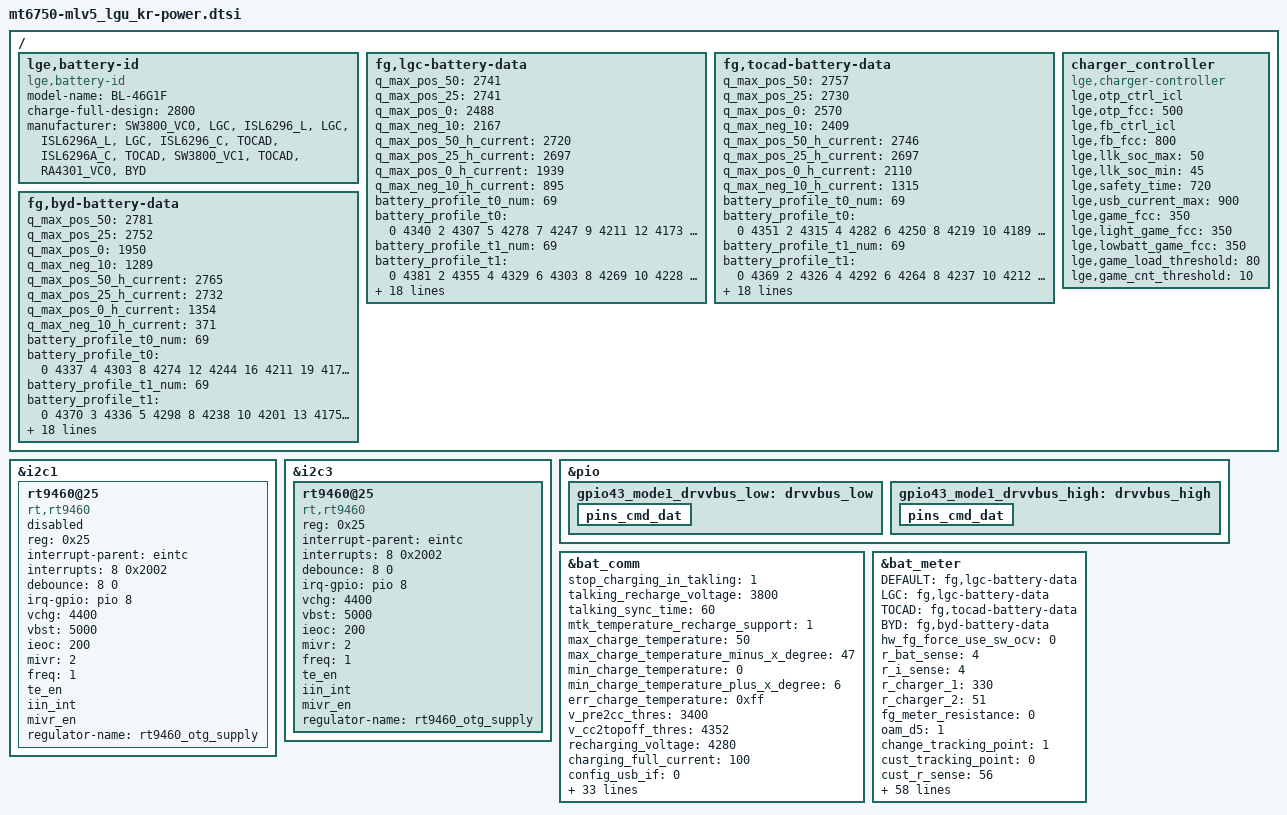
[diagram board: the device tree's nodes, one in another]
/*
 * LG Electronics LV5 power device tree source
 *
 * Copyright (c) 2016 LG Electronics Co., Ltd.
 *              http://www.lge.com
 *
 */

&i2c1 {
	rt9460@25 {
		status = "disabled";
		compatible = "rt,rt9460";
		reg = <0x25>;
		interrupt-parent = <&eintc>;
		interrupts = <8 0x2002>;
		debounce = <8 0>;
		irq-gpio = <&pio 8 0x2002>;
		vchg = <4400>;
		vbst = <5000>;
		ieoc = <200>;
		mivr = <2>;
		freq = <1>;
		te_en;
		iin_int;
		mivr_en;

		regulator-name = "rt9460_otg_supply";
	};
};

&i2c3 {
	rt9460@25 {
		status = "okay";
		compatible = "rt,rt9460";
		reg = <0x25>;
		interrupt-parent = <&eintc>;
		interrupts = <8 0x2002>;
		debounce = <8 0>;
		irq-gpio = <&pio 8 0x2002>;
		vchg = <4400>;
		vbst = <5000>;
		ieoc = <200>;
		mivr = <2>;
		freq = <1>;
		te_en;
		iin_int;
		mivr_en;

		regulator-name = "rt9460_otg_supply";
	};
};

/ {
	lge,battery-id{
		compatible = "lge,battery-id";

		model-name = "BL-46G1F";
		charge-full-design = <2800>;

		/* Auth ID - Vendor */
		manufacturer =
			"SW3800_VC0", "LGC",
			"ISL6296_L", "LGC",
			"ISL6296A_L", "LGC",
			"ISL6296_C", "TOCAD",
			"ISL6296A_C", "TOCAD",
			"SW3800_VC1", "TOCAD",
			"RA4301_VC0", "BYD";
	};
};

&pio {
	gpio43_mode1_drvvbus_low: drvvbus_low{
		pins_cmd_dat {
			/delete-property/ pins;
			/delete-property/ slew-rate;
			/delete-property/ output-low;
		};
	};
	gpio43_mode1_drvvbus_high: drvvbus_high{
		pins_cmd_dat {
			/delete-property/ pins;
			/delete-property/ slew-rate;
			/delete-property/ output-high;
		};
	};
};

&bat_comm {
	/* cust_charging.h */
	/* stop charging while in talking mode */
	stop_charging_in_takling = <1 >;
	talking_recharge_voltage = <3800 >;
	talking_sync_time = <60 >;

	/* Battery Temperature Protection */
	mtk_temperature_recharge_support = <1 >;
	max_charge_temperature = <50 >;
	max_charge_temperature_minus_x_degree = <47 >;
	min_charge_temperature = <0 >;
	min_charge_temperature_plus_x_degree = <6 >;
	err_charge_temperature = <0xff >;

	/* Linear Charging Threshold */
	v_pre2cc_thres = <3400 >;	/* unit: mV */
	v_cc2topoff_thres = <4352 >;
	recharging_voltage = <4280 >;
	charging_full_current = <100 >;	/* unit: mA */

	/* Charging Current Setting */
	config_usb_if = <0 >;
	usb_charger_current_suspend = <0 >;	/* Unit: 0.01 mA */
	usb_charger_current_unconfigured = <7000 >;	/* Unit: 0.01 mA */
	usb_charger_current_configured = <50000 >;	/* Unit: 0.01 mA */
	usb_charger_current = <50000 >;	/* Unit: 0.01 mA */
	ac_charger_current = <320000 >;	/* Unit: 0.01 mA */
	ac_charger_input_current = <90000 >;	/* Unit: 0.01 mA */
	non_std_ac_charger_current = <50000 >;	/* Unit: 0.01 mA */
	charging_host_charger_current = <90000 >;	/* Unit: 0.01 mA */
	apple_0_5a_charger_current = <50000 >;	/* Unit: 0.01 mA */
	apple_1_0a_charger_current = <90000 >;	/* Unit: 0.01 mA */
	apple_2_1a_charger_current = <90000 >;	/* Unit: 0.01 mA */

	/* charger error check */
	bat_low_temp_protect_enable = <0 >;
	v_charger_enable = <0 >;	/* 1:on , 0:off */
	v_charger_max = <10500 >;	/* unit: mV */
	v_charger_min = <4400 >;

	/*  Tracking TIME */
	onehundred_percent_tracking_time = <10 >;	/* Unit: second */
	npercent_tracking_time = <20 >;	/* Unit: second */
	sync_to_real_tracking_time = <60 >;	/* Unit: second */
	v_0percent_tracking = <3450 >;	/* Unit: mV */

	/* High battery support */
	high_battery_voltage_support = <1 >;

	mtk_pump_express_plus_support = <0 >;
	ta_start_battery_soc = <1 >;
	ta_stop_battery_soc = <100 >;
	ta_ac_charging_current = <220000 >;

	ta_ac_12v_input_current = <180000 >;
	ta_ac_9v_input_current = <180000 >;
	ta_ac_7v_input_current = <180000 >;

	ta_9v_support = <1 >;
	ta_12v_support = <0 >;

	typec_high_input_current = <150000>;
	typec_high_charging_current = <150000>;
	typec_medium_input_current = <150000>;
	typec_medium_charging_current = <150000>;
};


/* battery_profile */
&bat_meter {
	/* battery id */
	DEFAULT = "fg,lgc-battery-data";
	LGC = "fg,lgc-battery-data";
	TOCAD = "fg,tocad-battery-data";
	BYD = "fg,byd-battery-data";

	/* cust_battery_meter.h */
	hw_fg_force_use_sw_ocv = <0 >;
	/* ADC resistor  */
	r_bat_sense = <4 >;
	r_i_sense = <4 >;
	r_charger_1 = <330 >;
	r_charger_2 = <51 >;
	fg_meter_resistance = <0 >;

	/* Discharge percentage, 1: D5, 0: D2 */
	oam_d5 = <1 >;

	change_tracking_point = <1 >;
	/* SW OCV tracking setting */
	cust_tracking_point = <0 >;
	cust_r_sense = <56 >;
	cust_hw_cc = <0 >;
	aging_tuning_value = <103 >;
	cust_r_fg_offset = <0 >;
	ocv_board_compesate = <0 >;
	r_fg_board_base = <1000 >;
	r_fg_board_slope = <1000 >;
	car_tune_value = <99 >;

	/* HW Fuel gague  */
	current_detect_r_fg = <10 >;	/* Unit: mA */
	minerroroffset = <1000 >;
	fg_vbat_average_size = <18 >;
	r_fg_value = <10 >;	/* Unit: mOhm */

	/* HW Fuel gague 2.0*/
	difference_hwocv_rtc = <20 >;
	difference_hwocv_swocv = <30 >;
	difference_swocv_rtc = <30 >;

	difference_hwocv_vbat = <30>;
	difference_vbat_rtc = <30>;
	difference_swocv_rtc_pos = <15>;

	max_swocv = <1>;

	difference_voltage_update = <20>;
	aging1_load_soc = <70>;
	aging1_update_soc = <30>;
	batterypseudo100 = <95>;

	batterypseudo1 = <3>;

	q_max_by_sys = <1>;			/*8. qmax variant by system drop voltage.*/
	q_max_sys_voltage = <3350>;
	shutdown_gauge0 = <0>;
	shutdown_gauge1_xmins = <0>;
	shutdown_gauge1_mins = <60>;

	shutdown_system_voltage = <3300>;
	charge_tracking_time = <60>;
	discharge_tracking_time = <10>;

	recharge_tolerance = <2>;

	/* SW Fuel Gauge */
	max_hwocv = <5 >;
	max_vbat = <90 >;

	/* HW Fuel gague 1.0*/
	cust_poweron_delta_capacity_tolrance = <40 >;
	cust_poweron_low_capacity_tolrance = <5 >;
	cust_poweron_max_vbat_tolrance = <90 >;
	cust_poweron_delta_vbat_tolrance = <30 >;
	cust_poweron_delta_hw_sw_ocv_capacity_tolrance = <10 >;

	/* Fixed battery temperature */
	fixed_tbat_25 = <0 >;
	/* Dynamic change wake up period of battery thread when suspend */
	vbat_normal_wakeup = <3600 >;	/* Unit: mV */
	vbat_low_power_wakeup = <3500 >;	/* Unit: mV */
	normal_wakeup_period = <5400 >;	/* Unit: second */
	low_power_wakeup_period = <300 >;	/* Unit: second */
	close_poweroff_wakeup_period = <30 >;	/* Unit: second */

	init_soc_by_sw_soc = <1 >;
	sync_ui_soc_imm =<0>;
	mtk_enable_aging_algorithm = <1>;
	md_sleep_current_check = <1>;
	q_max_by_current = <0>;

	/* SOC track to SWOCV */
	cust_tracking_gap = <15 >;	/* start tracking gap */
	cust_trackingoffset = <0 >;	/* force offset to shift soc to 0 */
	cust_trackingen = <0 >;	/* 0:disable, 1:enable */

	/* keep min uisoc until voltage less than customization voltage of min uisoc */
	cust_min_uisoc_percentage = <2 >;
	cust_min_uisoc_voltage = <3300 >;

	rbat_pull_up_r = <62000 >;
	rbat_pull_up_volt = <1800 >;
};

/{
	/* LGC 2800mA Battery 3.4V cut off */
	fg,lgc-battery-data {
		/* Qmax for 0mA */
		q_max_pos_50 = <2741 >;
		q_max_pos_25 = <2741 >;
		q_max_pos_0 = <2488 >;
		q_max_neg_10 = <2167 >;
		/* Qmax for 400mA, said high current */
		q_max_pos_50_h_current = <2720 >;
		q_max_pos_25_h_current = <2697 >;
		q_max_pos_0_h_current = <1939 >;
		q_max_neg_10_h_current = <895 >;

		battery_profile_t0_num = <69 >;
		battery_profile_t0 = <
			0 4340 	2 4307 	5 4278 	7 4247 	9 4211
			12 4173 	14 4143 	16 4118 	18 4097 	21 4076
			23 4051 	25 4024 	28 3997 	30 3974 	32 3953
			35 3935 	37 3919 	39 3903 	42 3887 	44 3873
			46 3862 	48 3850 	51 3839 	53 3829 	55 3820
			58 3811 	60 3803 	62 3795 	65 3789 	67 3782
			69 3776 	72 3768 	74 3760 	76 3752 	78 3743
			81 3733 	83 3723 	85 3713 	88 3701 	90 3688
			92 3671 	95 3643 	97 3589 	99 3473 	100 3353
			100 3272 	100 3219 	100 3175 	100 3136 	100 3101
			100 3078 	100 3061 	100 3045 	100 3027 	100 3007
			100 2997 	100 3001 	100 2999 	100 2995 	100 2992
			100 2989 	100 2515 	100 2517 	100 2520 	100 2515
			100 2521 	100 2519 	100 2520 	100 2520
			>;
		battery_profile_t1_num = <69 >;
		battery_profile_t1 = <
			0 4381 	2 4355 	4 4329 	6 4303 	8 4269
			10 4228 	12 4190 	14 4163 	16 4140 	18 4119
			20 4099 	22 4082 	24 4061 	26 4039 	28 4017
			30 3997 	32 3980 	34 3963 	36 3946 	38 3928
			40 3909 	42 3891 	44 3874 	46 3860 	48 3848
			50 3838 	52 3829 	54 3820 	56 3812 	58 3804
			60 3798 	62 3791 	64 3788 	66 3783 	68 3778
			70 3774 	72 3769 	74 3763 	76 3757 	78 3748
			80 3739 	82 3729 	84 3718 	86 3706 	88 3696
			90 3686 	92 3676 	94 3660 	96 3617 	98 3522
			100 3430 	100 3388 	100 3359 	100 3337 	100 3319
			100 3304 	100 3292 	100 3281 	100 3270 	100 3261
			100 3252 	100 3244 	100 3237 	100 3230 	100 3223
			100 3217 	100 3210 	100 3204 	100 3204
			>;
		battery_profile_t2_num = <69 >;
		battery_profile_t2 = <
			0 4389 	2 4356 	4 4329 	5 4304 	7 4280
			9 4258 	11 4236 	13 4214 	15 4193 	16 4171
			18 4151 	20 4131 	22 4111 	24 4092 	25 4074
			27 4057 	29 4038 	31 4018 	33 4001 	35 3986
			36 3972 	38 3959 	40 3944 	42 3929 	44 3914
			45 3894 	47 3875 	49 3859 	51 3847 	53 3836
			55 3828 	56 3819 	58 3813 	60 3805 	62 3799
			64 3794 	65 3788 	67 3783 	69 3779 	71 3775
			73 3771 	74 3766 	76 3761 	78 3752 	80 3744
			82 3737 	84 3727 	85 3714 	87 3700 	89 3685
			91 3680 	93 3676 	94 3669 	96 3639 	98 3552
			100 3411 	100 3104 	100 3035 	100 2997 	100 2971
			100 2956 	100 2947 	100 2941 	100 2934 	100 2929
			100 2927 	100 2926 	100 2921 	100 2921
			>;
		battery_profile_t3_num = <69 >;
		battery_profile_t3 = <
			0 4394 	2 4358 	4 4329 	5 4304 	7 4279
			9 4256 	11 4233 	13 4212 	15 4189 	16 4169
			18 4148 	20 4127 	22 4107 	24 4088 	25 4069
			27 4051 	29 4033 	31 4016 	33 3999 	35 3984
			36 3968 	38 3954 	40 3940 	42 3927 	44 3913
			45 3896 	47 3874 	49 3856 	51 3844 	53 3834
			55 3825 	56 3817 	58 3809 	60 3802 	62 3796
			64 3789 	65 3784 	67 3779 	69 3775 	71 3770
			73 3763 	74 3750 	76 3743 	78 3736 	80 3729
			82 3722 	84 3713 	85 3700 	87 3687 	89 3671
			91 3666 	93 3662 	94 3654 	96 3624 	98 3542
			100 3411 	100 3141 	100 2970 	100 2926 	100 2903
			100 2890 	100 2880 	100 2875 	100 2869 	100 2865
			100 2863 	100 2862 	100 2857 	100 2857
			>;
		r_profile_t0_num = <69 >;
		r_profile_t0 = <
			795 4340 	795 4307 	830 4278 	853 4247 	908 4211
			1018 4173 	1108 4143 	1145 4118 	1163 4097 	1210 4076
			1228 4051 	1223 4024 	1213 3997 	1208 3974 	1208 3953
			1205 3935 	1213 3919 	1215 3903 	1223 3887 	1228 3873
			1245 3862 	1250 3850 	1263 3839 	1268 3829 	1278 3820
			1283 3811 	1308 3803 	1320 3795 	1325 3789 	1360 3782
			1380 3776 	1415 3768 	1438 3760 	1458 3752 	1488 3743
			1528 3733 	1575 3723 	1613 3713 	1673 3701 	1740 3688
			1788 3671 	1835 3643 	1880 3589 	1493 3473 	1383 3353
			1183 3272 	1053 3219 	940 3175 	845 3136 	765 3101
			703 3078 	655 3061 	615 3045 	590 3027 	543 3007
			520 2997 	563 3001 	558 2999 	1350 2995 	978 2992
			1365 2989 	180 2515 	185 2517 	193 2520 	180 2515
			195 2521 	190 2519 	193 2520 	193 2520
			>;
		r_profile_t1_num = <69 >;
		r_profile_t1 = <
			345 4381 	345 4355 	353 4329 	363 4303 	378 4269
			423 4228 	513 4190 	568 4163 	585 4140 	590 4119
			595 4099 	620 4082 	643 4061 	648 4039 	645 4017
			643 3997 	648 3980 	653 3963 	653 3946 	658 3928
			653 3909 	653 3891 	650 3874 	648 3860 	655 3848
			663 3838 	673 3829 	678 3820 	688 3812 	695 3804
			705 3798 	715 3791 	730 3788 	743 3783 	768 3778
			785 3774 	805 3769 	828 3763 	855 3757 	880 3748
			913 3739 	948 3729 	988 3718 	1028 3706 	1078 3696
			1140 3686 	1218 3676 	1308 3660 	1398 3617 	1498 3522
			1578 3430 	1470 3388 	1400 3359 	1350 3337 	1303 3319
			1265 3304 	1233 3292 	1218 3281 	1183 3270 	1155 3261
			1138 3252 	1123 3244 	1095 3237 	1098 3230 	1070 3223
			1068 3217 	1055 3210 	1040 3204 	1020 3204
			>;
		r_profile_t2_num = <69 >;
		r_profile_t2 = <
			145 4389 	145 4356 	143 4329 	143 4304 	140 4280
			143 4258 	145 4236 	143 4214 	148 4193 	145 4171
			145 4151 	150 4131 	153 4111 	155 4092 	160 4074
			163 4057 	168 4038 	168 4018 	173 4001 	175 3986
			178 3972 	185 3959 	185 3944 	188 3929 	185 3914
			170 3894 	160 3875 	148 3859 	145 3847 	145 3836
			148 3828 	145 3819 	150 3813 	150 3805 	155 3799
			158 3794 	158 3788 	160 3783 	163 3779 	163 3775
			165 3771 	163 3766 	165 3761 	160 3752 	165 3744
			173 3737 	178 3727 	183 3714 	188 3700 	188 3685
			203 3680 	223 3676 	255 3669 	278 3639 	313 3552
			403 3411 	765 3104 	603 3035 	508 2997 	435 2971
			398 2956 	380 2947 	358 2941 	358 2934 	330 2929
			320 2927 	318 2926 	318 2921 	323 2921
			>;
		r_profile_t3_num = <69 >;
		r_profile_t3 = <
			98 4394 	98 4358 	98 4329 	98 4304 	95 4279
			95 4256 	95 4233 	98 4212 	95 4189 	100 4169
			100 4148 	100 4127 	100 4107 	103 4088 	105 4069
			108 4051 	108 4033 	110 4016 	110 3999 	115 3984
			115 3968 	120 3954 	123 3940 	128 3927 	130 3913
			128 3896 	113 3874 	103 3856 	100 3844 	100 3834
			100 3825 	103 3817 	103 3809 	105 3802 	108 3796
			110 3789 	113 3784 	115 3779 	118 3775 	120 3770
			115 3763 	103 3750 	105 3743 	105 3736 	108 3729
			110 3722 	110 3713 	110 3700 	110 3687 	108 3671
			113 3666 	120 3662 	128 3654 	125 3624 	140 3542
			163 3411 	280 3141 	425 2970 	315 2926 	270 2903
			235 2890 	213 2880 	198 2875 	183 2869 	170 2865
			165 2863 	160 2862 	160 2857 	145 2857
			>;
	};
	/* TOCAD 2800mA Battery 3.4V cut off */
	fg,tocad-battery-data {
		/* Qmax for 0mA */
		q_max_pos_50 = <2757 >;
		q_max_pos_25 = <2730 >;
		q_max_pos_0 = <2570 >;
		q_max_neg_10 = <2409 >;
		/* Qmax for 400mA, said high current */
		q_max_pos_50_h_current = <2746 >;
		q_max_pos_25_h_current = <2697 >;
		q_max_pos_0_h_current = <2110 >;
		q_max_neg_10_h_current = <1315 >;

		battery_profile_t0_num = <69 >;
		battery_profile_t0 = <
			0 4351 	2 4315 	4 4282 	6 4250 	8 4219
			10 4189 	12 4162 	14 4138 	17 4113 	19 4090
			21 4068 	23 4047 	25 4026 	27 4004 	29 3985
			31 3967 	33 3948 	35 3930 	37 3910 	39 3891
			41 3874 	44 3858 	46 3845 	48 3833 	50 3822
			52 3813 	54 3807 	56 3801 	58 3797 	60 3792
			62 3789 	64 3785 	66 3782 	68 3778 	70 3773
			72 3769 	75 3762 	77 3755 	79 3746 	81 3734
			83 3723 	85 3711 	87 3700 	89 3691 	91 3682
			93 3673 	95 3659 	96 3649 	97 3645 	97 3640
			98 3636 	98 3633 	98 3629 	98 3625 	99 3621
			99 3616 	99 3612 	99 3608 	99 3603 	99 3599
			99 3594 	99 3590 	100 3585 	100 3581 	100 3577
			100 3573 	100 3569 	100 3564 	100 3400
			>;
		battery_profile_t1_num = <69 >;
		battery_profile_t1 = <
			0 4369 	2 4326 	4 4292 	6 4264 	8 4237
			10 4212 	12 4187 	14 4164 	16 4140 	17 4118
			19 4097 	21 4078 	23 4058 	25 4039 	27 4019
			29 4001 	31 3985 	33 3968 	35 3952 	37 3934
			39 3915 	41 3897 	43 3879 	45 3864 	47 3849
			49 3839 	50 3830 	52 3820 	54 3812 	56 3805
			58 3798 	60 3793 	62 3788 	64 3785 	66 3783
			68 3779 	70 3776 	72 3773 	74 3769 	76 3763
			78 3755 	80 3745 	81 3734 	83 3721 	85 3704
			87 3692 	89 3683 	91 3675 	93 3667 	95 3653
			97 3610 	98 3587 	98 3568 	98 3551 	99 3537
			99 3524 	99 3513 	99 3503 	99 3492 	99 3483
			99 3475 	100 3466 	100 3459 	100 3451 	100 3443
			100 3436 	100 3429 	100 3423 	100 3400
			>;
		battery_profile_t2_num = <69 >;
		battery_profile_t2 = <
			0 4386 	2 4357 	4 4335 	5 4314 	7 4292
			9 4271 	11 4250 	13 4228 	15 4207 	16 4186
			18 4165 	20 4144 	22 4124 	24 4104 	26 4085
			27 4067 	29 4048 	31 4030 	33 4014 	35 3997
			37 3982 	38 3968 	40 3953 	42 3936 	44 3917
			46 3896 	48 3878 	49 3864 	51 3852 	53 3842
			55 3833 	57 3825 	58 3817 	60 3811 	62 3804
			64 3798 	66 3793 	68 3788 	69 3783 	71 3779
			73 3775 	75 3770 	77 3765 	79 3758 	80 3750
			82 3742 	84 3729 	86 3716 	88 3697 	90 3688
			91 3686 	93 3683 	95 3678 	97 3642 	99 3538
			100 3348 	100 3141 	100 3064 	100 3030 	100 3010
			100 2997 	100 2989 	100 2979 	100 2972 	100 2965
			100 2960 	100 2957 	100 2952 	100 2952
			>;
		battery_profile_t3_num = <69 >;
		battery_profile_t3 = <
			0 4395 	2 4369 	4 4347 	5 4327 	7 4306
			9 4284 	11 4263 	13 4242 	14 4221 	16 4198
			18 4177 	20 4157 	22 4136 	24 4116 	25 4097
			27 4077 	29 4059 	31 4041 	33 4024 	34 4008
			36 3992 	38 3976 	40 3962 	42 3948 	43 3934
			45 3916 	47 3893 	49 3875 	51 3862 	52 3851
			54 3840 	56 3832 	58 3823 	60 3816 	62 3808
			63 3802 	65 3797 	67 3791 	69 3786 	71 3782
			72 3775 	74 3765 	76 3757 	78 3749 	80 3742
			81 3733 	83 3726 	85 3712 	87 3698 	89 3680
			90 3677 	92 3675 	94 3673 	96 3663 	98 3595
			99 3470 	100 3214 	100 3085 	100 3045 	100 3021
			100 3002 	100 2985 	100 2974 	100 2963 	100 2954
			100 2946 	100 2939 	100 2931 	100 2931
			>;
		r_profile_t0_num = <69 >;
		r_profile_t0 = <
			693 4351 	693 4315 	723 4282 	743 4250 	763 4219
			785 4189 	808 4162 	835 4138 	855 4113 	875 4090
			898 4068 	918 4047 	935 4026 	948 4004 	968 3985
			985 3967 	1000 3948 	1013 3930 	1015 3910 	1013 3891
			1008 3874 	1000 3858 	998 3845 	995 3833 	998 3822
			998 3813 	1010 3807 	1018 3801 	1030 3797 	1045 3792
			1068 3789 	1093 3785 	1123 3782 	1153 3778 	1183 3773
			1218 3769 	1245 3762 	1278 3755 	1315 3746 	1353 3734
			1400 3723 	1453 3711 	1518 3700 	1598 3691 	1700 3682
			1835 3673 	2035 3659 	2125 3649 	2115 3645 	2103 3640
			2093 3636 	2083 3633 	2078 3629 	2063 3625 	2060 3621
			2053 3616 	2035 3612 	2043 3608 	2023 3603 	2003 3599
			2005 3594 	2003 3590 	1970 3585 	1963 3581 	1958 3577
			1953 3573 	1948 3569 	1938 3564 	1520 3400
			>;
		r_profile_t1_num = <69 >;
		r_profile_t1 = <
			423 4369 	423 4326 	448 4292 	470 4264 	488 4237
			505 4212 	520 4187 	543 4164 	558 4140 	568 4118
			573 4097 	580 4078 	585 4058 	588 4039 	588 4019
			590 4001 	593 3985 	590 3968 	588 3952 	580 3934
			570 3915 	563 3897 	553 3879 	548 3864 	540 3849
			545 3839 	553 3830 	555 3820 	560 3812 	565 3805
			568 3798 	575 3793 	580 3788 	590 3785 	608 3783
			623 3779 	640 3776 	660 3773 	683 3769 	705 3763
			728 3755 	753 3745 	788 3734 	825 3721 	865 3704
			928 3692 	1015 3683 	1140 3675 	1333 3667 	1605 3653
			1988 3610 	1973 3587 	1928 3568 	1888 3551 	1863 3537
			1818 3524 	1795 3513 	1760 3503 	1740 3492 	1715 3483
			1710 3475 	1685 3466 	1685 3459 	1633 3451 	1658 3443
			1608 3436 	1625 3429 	1570 3423 	1528 3400
			>;
		r_profile_t2_num = <69 >;
		r_profile_t2 = <
			183 4386 	183 4357 	185 4335 	183 4314 	183 4292
			185 4271 	188 4250 	185 4228 	188 4207 	188 4186
			188 4165 	188 4144 	190 4124 	193 4104 	193 4085
			198 4067 	200 4048 	205 4030 	210 4014 	213 3997
			220 3982 	228 3968 	230 3953 	225 3936 	213 3917
			195 3896 	180 3878 	175 3864 	173 3852 	170 3842
			173 3833 	173 3825 	173 3817 	175 3811 	175 3804
			178 3798 	180 3793 	180 3788 	180 3783 	180 3779
			183 3775 	180 3770 	178 3765 	178 3758 	175 3750
			178 3742 	178 3729 	183 3716 	180 3697 	183 3688
			195 3686 	213 3683 	243 3678 	270 3642 	313 3538
			463 3348 	860 3141 	680 3064 	575 3030 	533 3010
			503 2997 	473 2989 	470 2979 	450 2972 	440 2965
			443 2960 	400 2957 	425 2952 	400 2952
			>;
		r_profile_t3_num = <69 >;
		r_profile_t3 = <
			100 4395 	100 4369 	98 4347 	100 4327 	103 4306
			100 4284 	103 4263 	103 4242 	105 4221 	103 4198
			103 4177 	108 4157 	105 4136 	108 4116 	110 4097
			110 4077 	113 4059 	115 4041 	115 4024 	120 4008
			123 3992 	125 3976 	135 3962 	140 3948 	148 3934
			143 3916 	123 3893 	110 3875 	105 3862 	103 3851
			100 3840 	103 3832 	105 3823 	108 3816 	105 3808
			108 3802 	110 3797 	113 3791 	115 3786 	120 3782
			115 3775 	108 3765 	103 3757 	103 3749 	103 3742
			100 3733 	103 3726 	100 3712 	103 3698 	98 3680
			100 3677 	103 3675 	113 3673 	115 3663 	118 3595
			135 3470 	233 3214 	715 3085 	628 3045 	555 3021
			520 3002 	493 2985 	453 2974 	425 2963 	403 2954
			390 2946 	350 2939 	358 2931 	368 2931
			>;
	};
	/* BYD 2800mA Battery 3.4V cut off */
	fg,byd-battery-data {
		/* Qmax for 0mA */
		q_max_pos_50 = <2781 >;
		q_max_pos_25 = <2752 >;
		q_max_pos_0 = <1950 >;
		q_max_neg_10 = <1289 >;
		/* Qmax for 400mA, said high current */
		q_max_pos_50_h_current = <2765 >;
		q_max_pos_25_h_current = <2732 >;
		q_max_pos_0_h_current = <1354 >;
		q_max_neg_10_h_current = <371 >;

		battery_profile_t0_num = <69 >;
		battery_profile_t0 = <
			0 4337 	4 4303 	8 4274 	12 4244 	16 4211
			19 4170 	23 4109 	27 4064 	31 4035 	35 4007
			39 3979 	43 3956 	46 3936 	50 3919 	54 3901
			58 3883 	62 3862 	66 3839 	70 3815 	74 3794
			77 3777 	81 3762 	85 3743 	89 3710 	93 3647
			97 3531 	98 3475 	99 3449 	99 3431 	100 3418
			100 3408 	100 3401 	100 3395 	100 3389 	100 3385
			100 3381 	100 3378 	100 3374 	100 3369 	100 3366
			100 3362 	100 3359 	100 3355 	100 3352 	100 3349
			100 3346 	100 3341 	100 3338 	100 3335 	100 3332
			100 3330 	100 3326 	100 3323 	100 3319 	100 3317
			100 3314 	100 3311 	100 3309 	100 3306 	100 3303
			100 3301 	100 3299 	100 3296 	100 3293 	100 3289
			100 3286 	100 3283 	100 3280 	100 3280
			>;
		battery_profile_t1_num = <69 >;
		battery_profile_t1 = <
			0 4370 	3 4336 	5 4298 	8 4238 	10 4201
			13 4175 	15 4151 	18 4126 	20 4100 	23 4074
			26 4051 	28 4027 	31 4001 	33 3974 	36 3953
			38 3937 	41 3925 	43 3914 	46 3903 	49 3890
			51 3878 	54 3866 	56 3855 	59 3843 	61 3833
			64 3821 	67 3810 	69 3797 	72 3784 	74 3771
			77 3757 	79 3743 	82 3729 	84 3717 	87 3710
			90 3704 	92 3694 	95 3663 	97 3578 	100 3414
			100 3314 	100 3274 	100 3253 	100 3236 	100 3223
			100 3210 	100 3197 	100 3186 	100 3180 	100 3173
			100 3168 	100 3163 	100 3156 	100 3151 	100 3145
			100 3140 	100 3134 	100 3128 	100 3121 	100 3118
			100 3111 	100 3108 	100 3102 	100 3098 	100 3094
			100 3083 	100 3074 	100 3063 	100 3063
			>;
		battery_profile_t2_num = <69 >;
		battery_profile_t2 = <
			0 4387 	2 4361 	4 4341 	5 4319 	7 4297
			9 4277 	11 4255 	13 4233 	14 4213 	16 4190
			18 4170 	20 4150 	22 4130 	24 4110 	25 4091
			27 4073 	29 4056 	31 4037 	33 4017 	34 4000
			36 3984 	38 3969 	40 3954 	42 3936 	44 3913
			45 3893 	47 3878 	49 3866 	51 3855 	53 3845
			54 3836 	56 3829 	58 3821 	60 3813 	62 3807
			64 3801 	65 3796 	67 3790 	69 3784 	71 3779
			73 3772 	74 3765 	76 3760 	78 3753 	80 3747
			82 3739 	83 3730 	85 3717 	87 3706 	89 3691
			91 3688 	93 3685 	94 3681 	96 3660 	98 3579
			100 3439 	100 3166 	100 3121 	100 3103 	100 3091
			100 3082 	100 3075 	100 3068 	100 3060 	100 3050
			100 3035 	100 3028 	100 3022 	100 3022
			>;
		battery_profile_t3_num = <69 >;
		battery_profile_t3 = <
			0 4396 	2 4371 	4 4349 	5 4330 	7 4308
			9 4288 	11 4266 	13 4245 	14 4224 	16 4202
			18 4181 	20 4160 	22 4140 	23 4120 	25 4101
			27 4081 	29 4063 	30 4045 	32 4028 	34 4010
			36 3994 	38 3978 	39 3964 	41 3949 	43 3932
			45 3909 	47 3888 	48 3874 	50 3862 	52 3851
			54 3842 	56 3833 	57 3825 	59 3817 	61 3810
			63 3803 	65 3797 	66 3792 	68 3786 	70 3780
			72 3773 	74 3760 	75 3751 	77 3744 	79 3735
			81 3728 	83 3723 	84 3712 	86 3702 	88 3689
			90 3679 	92 3677 	93 3675 	95 3669 	97 3625
			99 3528 	100 3352 	100 3097 	100 3019 	100 2981
			100 2952 	100 2935 	100 2925 	100 2916 	100 2903
			100 2896 	100 2897 	100 2886 	100 2886
			>;
		r_profile_t0_num = <69 >;
		r_profile_t0 = <
			1418 4337 	1418 4303 	1390 4274 	1355 4244 	1330 4211
			1323 4170 	1428 4109 	1613 4064 	1655 4035 	1650 4007
			1623 3979 	1603 3956 	1593 3936 	1588 3919 	1583 3901
			1580 3883 	1570 3862 	1565 3839 	1558 3815 	1563 3794
			1565 3777 	1585 3762 	1600 3743 	1625 3710 	1653 3647
			1725 3531 	1690 3475 	1625 3449 	1580 3431 	1550 3418
			1523 3408 	1503 3401 	1490 3395 	1475 3389 	1473 3385
			1455 3381 	1448 3378 	1445 3374 	1443 3369 	1433 3366
			1423 3362 	1405 3359 	1405 3355 	1385 3352 	1398 3349
			1368 3346 	1393 3341 	1370 3338 	1375 3335 	1383 3332
			1328 3330 	1363 3326 	1350 3323 	1368 3319 	1338 3317
			1360 3314 	1293 3311 	1348 3309 	1318 3306 	1303 3303
			1353 3301 	1308 3299 	1308 3296 	1313 3293 	1335 3289
			1368 3286 	1323 3283 	1378 3280 	1340 3280
			>;
		r_profile_t1_num = <69 >;
		r_profile_t1 = <
			825 4370 	825 4336 	848 4298 	868 4238 	1028 4201
			1068 4175 	1070 4151 	1060 4126 	1045 4100 	1030 4074
			1020 4051 	1010 4027 	995 4001 	975 3974 	965 3953
			965 3937 	968 3925 	968 3914 	968 3903 	963 3890
			960 3878 	963 3866 	968 3855 	968 3843 	978 3833
			980 3821 	980 3810 	988 3797 	990 3784 	998 3771
			1003 3757 	1010 3743 	1020 3729 	1035 3717 	1058 3710
			1090 3704 	1133 3694 	1173 3663 	1198 3578 	1290 3414
			1285 3314 	1190 3274 	1145 3253 	1105 3236 	1060 3223
			1030 3210 	1005 3197 	975 3186 	965 3180 	938 3173
			945 3168 	915 3163 	948 3156 	900 3151 	905 3145
			915 3140 	920 3134 	955 3128 	938 3121 	820 3118
			938 3111 	820 3108 	823 3102 	925 3098 	928 3094
			1000 3083 	1000 3074 	1020 3063 	903 3063
			>;
		r_profile_t2_num = <69 >;
		r_profile_t2 = <
			190 4387 	190 4361 	190 4341 	185 4319 	173 4297
			173 4277 	170 4255 	165 4233 	165 4213 	150 4190
			148 4170 	150 4150 	160 4130 	168 4110 	173 4091
			175 4073 	180 4056 	185 4037 	190 4017 	193 4000
			198 3984 	198 3969 	200 3954 	195 3936 	175 3913
			168 3893 	165 3878 	163 3866 	165 3855 	163 3845
			165 3836 	168 3829 	170 3821 	163 3813 	168 3807
			170 3801 	173 3796 	175 3790 	175 3784 	178 3779
			173 3772 	168 3765 	170 3760 	175 3753 	183 3747
			180 3739 	170 3730 	160 3717 	158 3706 	150 3691
			153 3688 	155 3685 	163 3681 	163 3660 	170 3579
			205 3439 	923 3166 	818 3121 	765 3103 	753 3091
			768 3082 	753 3075 	705 3068 	653 3060 	638 3050
			668 3035 	593 3028 	590 3022 	648 3022
			>;
		r_profile_t3_num = <69 >;
		r_profile_t3 = <
			103 4396 	103 4371 	100 4349 	103 4330 	100 4308
			103 4288 	103 4266 	105 4245 	105 4224 	103 4202
			103 4181 	103 4160 	105 4140 	108 4120 	108 4101
			108 4081 	110 4063 	113 4045 	118 4028 	120 4010
			120 3994 	125 3978 	130 3964 	138 3949 	138 3932
			120 3909 	105 3888 	103 3874 	100 3862 	100 3851
			103 3842 	103 3833 	105 3825 	105 3817 	108 3810
			108 3803 	110 3797 	113 3792 	115 3786 	118 3780
			115 3773 	108 3760 	105 3751 	108 3744 	103 3735
			105 3728 	110 3723 	105 3712 	108 3702 	108 3689
			103 3679 	108 3677 	113 3675 	120 3669 	115 3625
			130 3528 	173 3352 	755 3097 	560 3019 	468 2981
			423 2952 	390 2935 	315 2925 	333 2916 	310 2903
			283 2896 	265 2897 	295 2886 	305 2886
			>;
	};
};

/ {
	charger_controller: charger_controller {
		status = "ok";
		compatible = "lge,charger-controller";

		lge,otp_ctrl_icl;
		lge,otp_fcc = <500>;

		lge,fb_ctrl_icl;
		lge,fb_fcc = <800>;

		lge,llk_soc_max = <50>;
		lge,llk_soc_min = <45>;

		lge,safety_time = <720>; /*min*/

		lge,usb_current_max = <900>;

		/* BCCT by GPU load */
		lge,game_fcc = <350>;		/* CC for heavy game, empty value = unvote game mode in CC */
		lge,light_game_fcc = <350>;		/* CC for light game, empty value = game_fcc */
		lge,lowbatt_game_fcc = <350>;	/* CC for low battery in game, empty value = game_fcc */
		lge,game_load_threshold = <80>;	/* GPU threshold value for heavy game check */
		lge,game_cnt_threshold = <10>;	/* Counting threshold value for light game check */
	};
};
